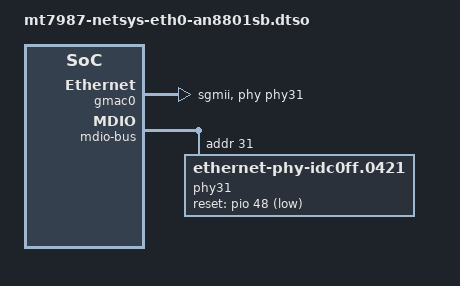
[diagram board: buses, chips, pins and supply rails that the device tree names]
// SPDX-License-Identifier: (GPL-2.0 OR MIT)

/dts-v1/;
/plugin/;

/ {
	fragment@0 {
		target-path = "/soc_netsys/ethernet@15100000";
		__overlay__ {
			gmac0: mac@0 {
				compatible = "mediatek,eth-mac";
				reg = <0>;
				phy-mode = "sgmii";
				phy-handle = <&phy31>;
				pcs-handle = <&sgmiipcs0>;
			};
		};
	};

	fragment@1 {
		target-path = "/soc_netsys/ethernet@15100000/mdio-bus";
		__overlay__ {
			phy31: phy@31 {
				compatible = "ethernet-phy-idc0ff.0421";
				reg = <31>;
				reset-gpios = <&pio 48 1>;
				reset-assert-us = <10000>;
				reset-deassert-us = <10000>;
				phy-mode = "sgmii";
				eee-broken-100tx;
				eee-broken-1000t;
			};
		};
	};

	fragment@2 {
		target-path = "/soc_netsys/hnat@15000000";
		__overlay__ {
			mtketh-lan = "eth0";
		};
	};
};

